# AT32F421 register map
Vendor: Keil; Series: AT32F421; File version: 1.0
CPU: CM4 r0p1, little endian, no MPU, FPU, 4 interrupt priority bits
Registers are 32-bit, read-write, reset 0x0 unless marked. A register's access mark holds for its fields unless they carry their own. Offsets are from the block's base; [hi:lo] are bit positions; lines under a group give offsets from that group; {n}, {i} and the like mark numbered series.

## DMA1 — DMA controller
Base 0x40020000
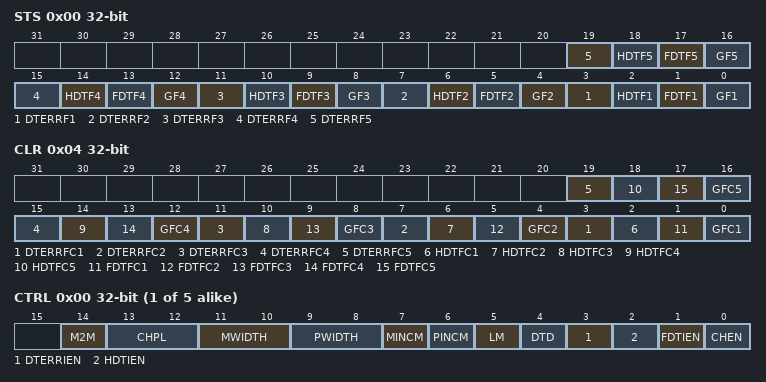
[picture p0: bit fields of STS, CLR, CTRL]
0x00 STS ro — DMA status register (DMA_STS)
  [4n-1] DTERRF{n} (n=1..5) — Channel {n} data transfer error event flag
  [4n-2] HDTF{n} (n=1..5) — Channel {n} half data transfer event flag
  [4n-3] FDTF{n} (n=1..5) — Channel {n} full data transfer event flag
  [4n-4] GF{n} (n=1..5) — Channel {n} Global event flag
0x04 CLR — DMA flag clear register (DMA_CLR)
  [4n-1] DTERRFC{n} (n=1..5) — Channel {n} data transfer error flag clear
  [4n-2] HDTFC{n} (n=1..5) — Channel {n} half data transfer flag clear
  [4n-3] FDTFC{n} (n=1..5) — Channel {n} full data transfer flag clear
  [4n-4] GFC{n} (n=1..5) — Channel {n} Global flag clear
0x08 Channel{i} (i=1..5; step 0x14) group — DMA Channel {i}
  0x00 CTRL — DMA channel configuration register
    [14] M2M — Memory to memory mode
      on read: 0=Disabled (Memory to memory mode is disabled); 1=Enabled (Memory to memory mode is enabled) | on write: 0=Disable (Memory to memory mode disable); 1=Enable (Memory to memory mode enable)
    [13:12] CHPL — Channel Priority level
      0=Low; 1=Medium; 2=High; 3=VeryHigh
    [11:10] MWIDTH — Memory data bit width
      0=bit8 (8 bits); 1=bit16 (16 bits); 2=bit32 (32 bits)
    [9:8] PWIDTH — Peripheral data bit width
      0=bit8 (8 bits); 1=bit16 (16 bits); 2=bit32 (32 bits)
    [7] MINCM — Memory address increment mode
      on read: 0=Disabled (Memory address increment is disabled); 1=Enabled (Memory address increment is enabled) | on write: 0=Disable (Memory address increment disable); 1=Enable (Memory address increment enable)
    [6] PINCM — Peripheral address increment mode
      on read: 0=Disabled (Peripheral address increment is disabled); 1=Enabled (Peripheral address increment is enabled) | on write: 0=Disable (Peripheral address increment disable); 1=Enable (Peripheral address increment enable)
    [5] LM — Loop mode
      on read: 0=Disabled (Circular mode is disabled); 1=Enabled (Circular mode is enabled) | on write: 0=Disable (Circular mode disable); 1=Enable (Circular mode enable)
    [4] DTD — Data transfer direction
      0=Peripherals (Read from peripherals); 1=Memory (Read from memory)
    [3] DTERRIEN — Data transfer error interrupt enable
      on read: 0=Disabled (Data transfer error interrupt is disabled); 1=Enabled (Data transfer error interrupt is enabled) | on write: 0=Disable (Data transfer error interrupt disable); 1=Enable (Data transfer error interrupt enable)
    [2] HDTIEN — Half data transfer interrupt enable
      on read: 0=Disabled (Half-transfer interrupt is disabled); 1=Enabled (Half-transfer interrupt is enabled) | on write: 0=Disable (Half-transfer interrupt disable); 1=Enable (Half-transfer interrupt enable)
    [1] FDTIEN — Full data transfer interrupt enable
      on read: 0=Disabled (Transfer complete interrupt is disabled); 1=Enabled (Transfer complete interrupt is enabled) | on write: 0=Disable (Transfer complete interrupt disable); 1=Enable (Transfer complete interrupt enable)
    [0] CHEN — Channel enable
      on read: 0=Disabled (Channel is disabled); 1=Enabled (Channel is enabled) | on write: 0=Disable (Channel disable); 1=Enable (Channel enable)
  0x04 DTCNT 16-bit — DMA channel number of data to transfer register
  0x08 PADDR — DMA channel peripheral base address register
  0x0C MADDR — DMA channel memory base address register

## WDT — Watchdog
Base 0x40003000
0x00 CMD — Command register
  [15:0] CMD
    0x5555=Unlock write-protected WDT_DIV and WDT_RLD; 0xAAAA=Reload counter; 0xCCCC=Enable WDT. If the hardware watchdog has been enabled, ignore this operation.
0x04 DIV — Division register
  [2:0] DIV — Division divider
    0=LICK divided by 4; 1=LICK divided by 8; 2=LICK divided by 16; 3=LICK divided by 32; 4=LICK divided by 64; 5=LICK divided by 128; 6=LICK divided by 256; 7=div256_2 (LICK divided by 256)
0x08 RLD reset 0xFFF — Reload register
  [11:0] RLD — Reload value
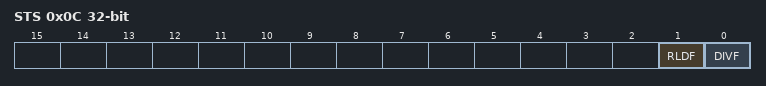
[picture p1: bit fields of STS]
0x0C STS ro — Status register
  [1] RLDF — Reload value update complete flag
    0=Complete (Reload value update complete); 1=InProgress (Reload value update is in process)
  [0] DIVF — Division value update complete flag
    0=Complete (Division value update complete); 1=InProgress (Division value update is in process)
